# EFM32HG321F64 register map
File version: 5.8.2
Silicon Labs EFM32HG321F64 Cortex-M MCU
CPU: CM0PLUS r0p1, little endian, no MPU, no FPU, 3 interrupt priority bits
Registers are 32-bit, read-write, reset 0x0 unless marked. A register's access mark holds for its fields unless they carry their own. Offsets are from the block's base; lines under a group give offsets from that group; [hi:lo] are bit positions; {n}, {i} and the like mark numbered series; 'fields as' and 'values as' point back to an identical list; <NAME> marks a mode.

## Memory map
0x40000000 VCMP size 0x400
0x40001000 ACMP0 size 0x400
0x40002000 ADC0 size 0x400
0x40004000 IDAC0 size 0x400
0x40006000 GPIO size 0x1000
0x4000A000 I2C0 size 0x400
0x4000C000 USART0 size 0x400
0x4000C400 USART1 size 0x400
0x40010000 TIMER0 size 0x400
0x40010400 TIMER1 size 0x400
0x40010800 TIMER2 size 0x400
0x40080000 RTC size 0x400
0x40084000 LEUART0 size 0x400
0x40086000 PCNT0 size 0x400
0x40088000 WDOG size 0x400
0x400C0000 MSC size 0x400
0x400C2000 DMA size 0x2000
0x400C4000 USB blocks up to offset 0x3D000
0x400C6000 EMU size 0x400
0x400C8000 CMU size 0x400
0x400CA000 RMU size 0x400
0x400CC000 PRS size 0x400
0xF0040000 MTB size 0x40000

## Interrupts
0 DMA
1 GPIO_EVEN (GPIO)
2 TIMER0
3 ACMP0
4 ADC0
5 I2C0
6 GPIO_ODD (GPIO)
7 TIMER1
8 USART1_RX (USART1)
9 USART1_TX (USART1)
10 LEUART0
11 PCNT0
12 RTC
13 CMU
14 VCMP
15 MSC
17 USART0_RX (USART0)
18 USART0_TX (USART0)
19 USB
20 TIMER2

## Further device data
name=Copyright 2019 Silicon Laboratories, Inc., flashBaseAddress=0x00000000, flashSize=0x00010000, flashAccessTypes=rx, sramBaseAddress=0x20000000, sramSize=0x00002000, sramAccessTypes=rwx

## DMA
Base 0x400C2000
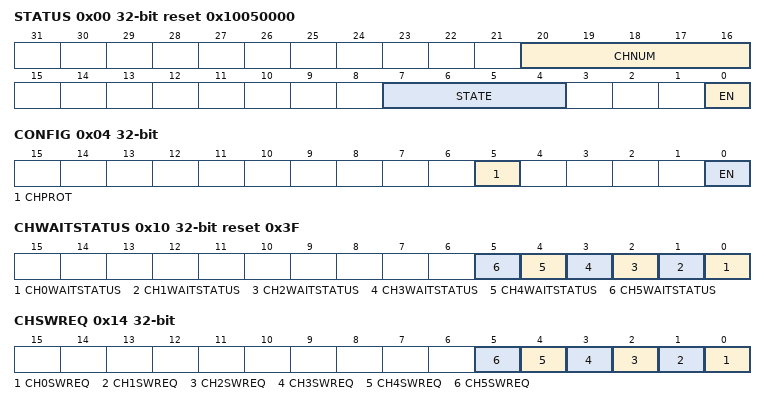
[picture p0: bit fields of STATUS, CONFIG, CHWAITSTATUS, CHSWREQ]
0x00 STATUS ro reset 0x10050000 — DMA Status Registers
  [20:16] CHNUM — Channel Number
  [7:4] STATE — Control Current State
    0=IDLE; 1=RDCHCTRLDATA (Reading channel controller data); 2=RDSRCENDPTR (Reading source data end pointer); 3=RDDSTENDPTR (Reading destination data end pointer); 4=RDSRCDATA (Reading source data); 5=WRDSTDATA (Writing destination data); 6=WAITREQCLR (Waiting for DMA request to clear); 7=WRCHCTRLDATA (Writing channel controller data); 8=STALLED; 9=DONE; 10=PERSCATTRANS (Peripheral scatter-gather transition)
  [0] EN — DMA Enable Status
0x04 CONFIG wo — DMA Configuration Register
  [5] CHPROT — Channel Protection Control
  [0] EN — Enable DMA
0x08 CTRLBASE — Channel Control Data Base Pointer Register
  [31:0] CTRLBASE — Channel Control Data Base Pointer
0x0C ALTCTRLBASE ro reset 0x80 — Channel Alternate Control Data Base Pointer Register
  [31:0] ALTCTRLBASE — Channel Alternate Control Data Base Pointer
0x10 CHWAITSTATUS ro reset 0x3F — Channel Wait on Request Status Register
  [n] CH{n}WAITSTATUS (n=0..5) — Channel {n} Wait on Request Status
0x14 CHSWREQ wo — Channel Software Request Register
  [n] CH{n}SWREQ (n=0..5) — Channel {n} Software Request
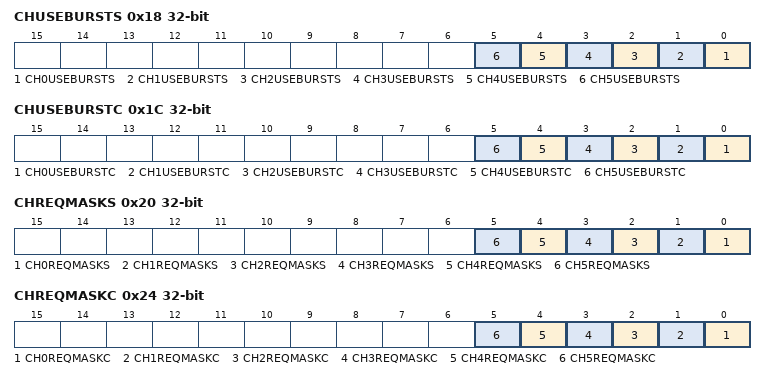
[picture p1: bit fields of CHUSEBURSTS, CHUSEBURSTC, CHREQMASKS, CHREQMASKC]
0x18 CHUSEBURSTS — Channel Useburst Set Register
  [n] CH{n}USEBURSTS (n=0..5) — Channel {n} Useburst Set
0x1C CHUSEBURSTC wo — Channel Useburst Clear Register
  [n] CH{n}USEBURSTC (n=0..5) — Channel {n} Useburst Clear
0x20 CHREQMASKS wo — Channel Request Mask Set Register
  [n] CH{n}REQMASKS (n=0..5) — Channel {n} Request Mask Set
0x24 CHREQMASKC wo — Channel Request Mask Clear Register
  [n] CH{n}REQMASKC (n=0..5) — Channel {n} Request Mask Clear
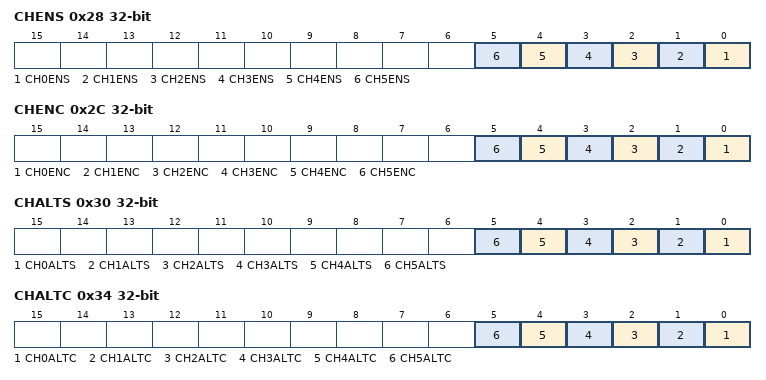
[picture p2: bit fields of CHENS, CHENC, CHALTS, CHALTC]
0x28 CHENS wo — Channel Enable Set Register
  [n] CH{n}ENS (n=0..5) — Channel {n} Enable Set
0x2C CHENC wo — Channel Enable Clear Register
  [n] CH{n}ENC (n=0..5) — Channel {n} Enable Clear
0x30 CHALTS wo — Channel Alternate Set Register
  [n] CH{n}ALTS (n=0..5) — Channel {n} Alternate Structure Set
0x34 CHALTC wo — Channel Alternate Clear Register
  [n] CH{n}ALTC (n=0..5) — Channel {n} Alternate Clear
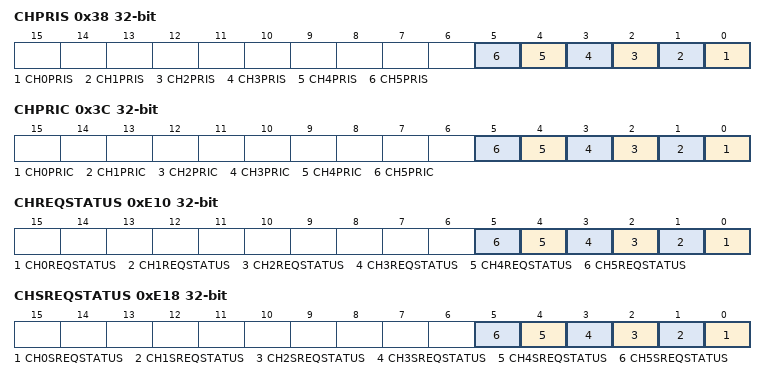
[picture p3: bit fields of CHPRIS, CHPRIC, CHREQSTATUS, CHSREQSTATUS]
0x38 CHPRIS wo — Channel Priority Set Register
  [n] CH{n}PRIS (n=0..5) — Channel {n} High Priority Set
0x3C CHPRIC wo — Channel Priority Clear Register
  [n] CH{n}PRIC (n=0..5) — Channel {n} High Priority Clear
0x4C ERRORC — Bus Error Clear Register
  [0] ERRORC — Bus Error Clear
0xE10 CHREQSTATUS ro — Channel Request Status
  [n] CH{n}REQSTATUS (n=0..5) — Channel {n} Request Status
0xE18 CHSREQSTATUS ro — Channel Single Request Status
  [n] CH{n}SREQSTATUS (n=0..5) — Channel {n} Single Request Status
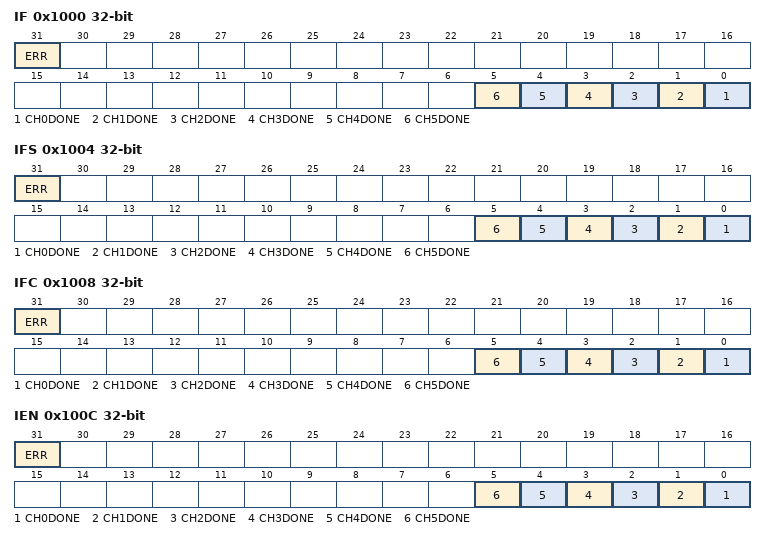
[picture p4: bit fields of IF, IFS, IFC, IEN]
0x1000 IF ro — Interrupt Flag Register
  [31] ERR — DMA Error Interrupt Flag
  [n] CH{n}DONE (n=0..5) — DMA Channel {n} Complete Interrupt Flag
0x1004 IFS wo — Interrupt Flag Set Register
  [31] ERR — DMA Error Interrupt Flag Set
  [n] CH{n}DONE (n=0..5) — DMA Channel {n} Complete Interrupt Flag Set
0x1008 IFC wo — Interrupt Flag Clear Register
  [31] ERR — DMA Error Interrupt Flag Clear
  [n] CH{n}DONE (n=0..5) — DMA Channel {n} Complete Interrupt Flag Clear
0x100C IEN — Interrupt Enable register
  [31] ERR — DMA Error Interrupt Flag Enable
  [n] CH{n}DONE (n=0..5) — DMA Channel {n} Complete Interrupt Enable
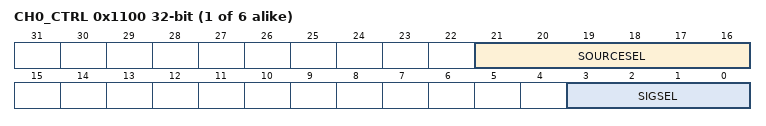
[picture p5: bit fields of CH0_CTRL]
{0x1100+4i} CH{i}_CTRL (i=0..5) — Channel Control Register
  [21:16] SOURCESEL — Source Select
    0=NONE (No source selected); 8=ADC0 (Analog to Digital Converter 0); 12=USART0 (Universal Synchronous/Asynchronous Receiver/Transmitter 0); 13=USART1 (Universal Synchronous/Asynchronous Receiver/Transmitter 1); 16=LEUART0 (Low Energy UART 0); 20=I2C0; 24=TIMER0; 25=TIMER1; 26=TIMER2; 48=MSC
  [3:0] SIGSEL — Signal Select

## Licence text in the file
******************************************************************************* * @version 5.8.2 ******************************************************************************* * # License * Copyright 2019 Silicon Laboratories Inc. www.silabs.com ******************************************************************************* * * SPDX-License-Identifier: Zlib * * The licensor of this software is Silicon Laboratories Inc. * * This software is provided 'as-is', without any express or implied * warranty. In no event will the authors be held liable for any damages * arising from the use of this software. * * Permission is granted to anyone to use this software for any purpose, * including commercial applications, and to alter it and redistribute it * freely, subject to the following restrictions: * * 1. The origin of this software must not be misrepresented; you must not * claim that you wrote the original software. If you use this software * in a product, an acknowledgment in the product documentation would be * appreciated but is not required. * 2. Altered source versions must be plainly marked as such, and must not be * misrepresented as being the original software. * 3. This notice may not be removed or altered from any source distribution. * *******************************************************************************
